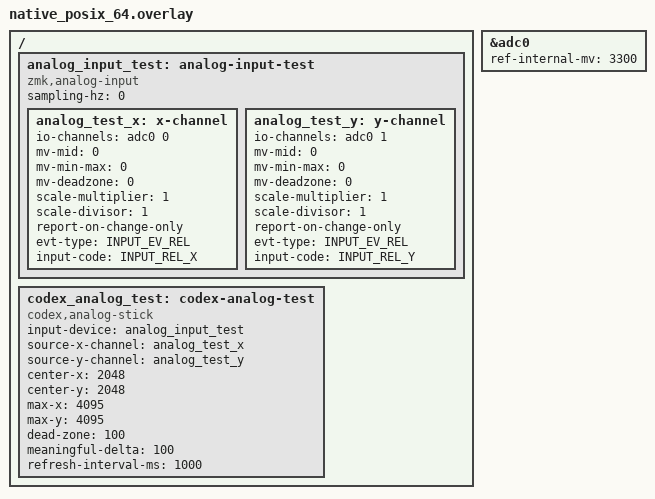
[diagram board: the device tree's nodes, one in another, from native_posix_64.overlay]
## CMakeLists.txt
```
cmake_minimum_required(VERSION 3.20.0)
set(KCONFIG_ROOT ${CMAKE_CURRENT_SOURCE_DIR}/Kconfig)
# The analog tests exercise the pinned badjeff driver, not a mock.  Twister
# passes the module under test through the cached ZEPHYR_EXTRA_MODULES value;
# replace that cache entry before Zephyr discovers modules so the real driver
# contributes its Kconfig, DTS bindings, and source.  The Codex module is
# added below with a distinct binary directory because its relative module
# name ("..") otherwise resolves to the application binary directory.
set(ZEPHYR_EXTRA_MODULES
  "${CMAKE_CURRENT_SOURCE_DIR}/../../../zmk-analog-input-driver"
  CACHE STRING "Modules required by Codex input tests" FORCE
)
# The adapter is added manually below, so declare its DTS root now. The
# fixture also needs ZMK's vendor-prefix registry for zmk,analog-input; DTS
# generation occurs during find_package(Zephyr), before add_subdirectory.
list(APPEND DTS_ROOT
  "${CMAKE_CURRENT_SOURCE_DIR}/../.."
  "${CMAKE_CURRENT_SOURCE_DIR}/../../../zmk/app"
)
# Zephyr discovers the Codex module during find_package(), so publish the
# exact pinned source path before module CMake is evaluated.
set(CODEX_ZMK_ACTIVITY_SOURCE
  "${CMAKE_CURRENT_SOURCE_DIR}/../../../zmk/app/src/activity.c"
  CACHE FILEPATH "Pinned ZMK activity source exercised by this fixture" FORCE
)
find_package(Zephyr REQUIRED HINTS $ENV{ZEPHYR_BASE})
project(codex_input)

execute_process(
  COMMAND west list zmk -f {abspath}
  OUTPUT_VARIABLE ZMK_SOURCE_DIR
  OUTPUT_STRIP_TRAILING_WHITESPACE
  COMMAND_ERROR_IS_FATAL ANY
)

# Compile the exact pinned ZMK activity implementation in this fixture.  The
# Codex module must replace this source through the same audited path used by
# production, not through a test-only activity mock.
target_sources(app PRIVATE "${CODEX_ZMK_ACTIVITY_SOURCE}")

if(NOT TARGET codex_micro)
  add_subdirectory(${CMAKE_CURRENT_SOURCE_DIR}/../..
    ${CMAKE_CURRENT_BINARY_DIR}/codex_micro_module)
endif()

target_include_directories(app PRIVATE
  ${CMAKE_CURRENT_SOURCE_DIR}/../..
  ${CMAKE_CURRENT_SOURCE_DIR}/../../include
  ${ZMK_SOURCE_DIR}/app/include
)
target_include_directories(codex_micro PRIVATE ${ZMK_SOURCE_DIR}/app/include)
target_link_libraries(app PRIVATE codex_micro)
target_sources(app PRIVATE
  src/key_test.c
  src/analog_test.c
  src/activity_test_support.c
  src/touch_state_test.c
)

zephyr_ld_options(
  -Wl,--wrap=codex_zmk_activity_note
  -Wl,--wrap=zmk_keymap_highest_layer_active
  -Wl,--wrap=zmk_keymap_layer_index_to_id
  -Wl,--wrap=zmk_keymap_layer_active
  -Wl,--wrap=zmk_keymap_layer_activate
  -Wl,--wrap=zmk_keymap_layer_deactivate
  -Wl,--wrap=zmk_ble_active_profile_index
  -Wl,--wrap=zmk_ble_prof_select
  -Wl,--wrap=zmk_ble_clear_bonds
  -Wl,--wrap=zmk_endpoints_select_transport
  -Wl,--wrap=zmk_endpoints_selected
)
```

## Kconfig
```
source "Kconfig.zephyr"

# The test application adds the Codex module manually after Zephyr configures;
# include its symbols now so the fixture exercises the production adapter.
rsource "../../Kconfig"

config ZMK_USB
    bool
    default y

config ZMK_HID_REPORT_TYPE_HKRO
    bool
    default y

config ZMK_HID_REPORT_TYPE_NKRO
    bool
    default n

config ZMK_HID_CONSUMER_REPORT_USAGES_FULL
    bool
    default y

config ZMK_HID_CONSUMER_REPORT_USAGES_BASIC
    bool
    default n

config ZMK_HID_INDICATORS
    bool
    default y

config ZMK_POINTING
    bool
    default y

config ZMK_IDLE_TIMEOUT
    int
    default 40

config ZMK_LOG_LEVEL
    int
    default 0

config NRF_STORE_REBOOT_TYPE_GPREGRET
    bool
    default n
```

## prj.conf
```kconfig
CONFIG_ZTEST=y
CONFIG_ZTEST_NEW_API=y
CONFIG_CODEX_MICRO=y
CONFIG_CODEX_ANALOG_STICK=y
CONFIG_INPUT=y
CONFIG_SENSOR=y
CONFIG_ADC=y
CONFIG_ADC_EMUL=y
CONFIG_ANALOG_INPUT=y
CONFIG_ANALOG_INPUT_USE_DTS_ADC_CH_CFG=n
CONFIG_ANALOG_INPUT_ADC_RES=12
CONFIG_ENABLE_HID_INT_OUT_EP=n
```

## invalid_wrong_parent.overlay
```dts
#include <zephyr/dt-bindings/input/input-event-codes.h>

/ {
    wrong_analog_source: wrong-analog-source {
        compatible = "zmk,analog-input";
        sampling-hz = <0>;
        wrong_x: x-channel {
            io-channels = <&adc0 0>;
            mv-mid = <0>; mv-min-max = <0>; mv-deadzone = <0>;
            scale-multiplier = <1>; scale-divisor = <1>;
            report-on-change-only; evt-type = <INPUT_EV_REL>; input-code = <INPUT_REL_X>;
        };
        wrong_y: y-channel {
            io-channels = <&adc0 1>;
            mv-mid = <0>; mv-min-max = <0>; mv-deadzone = <0>;
            scale-multiplier = <1>; scale-divisor = <1>;
            report-on-change-only; evt-type = <INPUT_EV_REL>; input-code = <INPUT_REL_Y>;
        };
    };
    codex_analog_test: codex-analog-test {
        compatible = "codex,analog-stick";
        input-device = <&wrong_analog_source>;
        /* Deliberately wrong: these producer children have another parent. */
        source-x-channel = <&analog_test_x>;
        source-y-channel = <&analog_test_y>;
        center-x = <2048>; center-y = <2048>; max-x = <4095>; max-y = <4095>;
        dead-zone = <100>; meaningful-delta = <100>; refresh-interval-ms = <20>;
    };
};
```

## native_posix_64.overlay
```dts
#include <zephyr/dt-bindings/input/input-event-codes.h>

&adc0 {
    ref-internal-mv = <3300>;
};

/ {
    analog_input_test: analog-input-test {
        compatible = "zmk,analog-input";
        sampling-hz = <0>;

        analog_test_x: x-channel {
            io-channels = <&adc0 0>;
            mv-mid = <0>;
            mv-min-max = <0>;
            mv-deadzone = <0>;
            scale-multiplier = <1>;
            scale-divisor = <1>;
            report-on-change-only;
            evt-type = <INPUT_EV_REL>;
            input-code = <INPUT_REL_X>;
        };

        analog_test_y: y-channel {
            io-channels = <&adc0 1>;
            mv-mid = <0>;
            mv-min-max = <0>;
            mv-deadzone = <0>;
            scale-multiplier = <1>;
            scale-divisor = <1>;
            report-on-change-only;
            evt-type = <INPUT_EV_REL>;
            input-code = <INPUT_REL_Y>;
        };
    };

    codex_analog_test: codex-analog-test {
        compatible = "codex,analog-stick";
        input-device = <&analog_input_test>;
        source-x-channel = <&analog_test_x>;
        source-y-channel = <&analog_test_y>;
        center-x = <2048>;
        center-y = <2048>;
        max-x = <4095>;
        max-y = <4095>;
        dead-zone = <100>;
        meaningful-delta = <100>;
        /* Timer-specific tests use a short override and cancel it; keep the
         * shared callback fixture from leaking a refresh into key tests. */
        refresh-interval-ms = <1000>;
    };
};
```

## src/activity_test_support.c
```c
#include <errno.h>
#include <stddef.h>

#include <zephyr/logging/log.h>

#include <zmk/event_manager.h>
#include <zmk/events/activity_state_changed.h>

#include "activity_test_support.h"

LOG_MODULE_REGISTER(zmk, CONFIG_ZMK_LOG_LEVEL);

const struct zmk_event_type zmk_event_zmk_activity_state_changed = {
    .name = "zmk_activity_state_changed",
};
const struct zmk_event_type zmk_event_zmk_position_state_changed = {
    .name = "zmk_position_state_changed",
};
const struct zmk_event_type zmk_event_zmk_sensor_event = {
    .name = "zmk_sensor_event",
};

static size_t activity_state_event_count;
static size_t activity_note_call_count;
static size_t activity_note_failures_remaining;

extern int __real_codex_zmk_activity_note(void);

int __wrap_codex_zmk_activity_note(void)
{
    activity_note_call_count++;
    if (activity_note_failures_remaining > 0U) {
        activity_note_failures_remaining--;
        return -EIO;
    }
    return __real_codex_zmk_activity_note();
}

int raise_zmk_activity_state_changed(struct zmk_activity_state_changed event)
{
    ARG_UNUSED(event);
    activity_state_event_count++;
    return 0;
}

void codex_activity_test_reset_events(void)
{
    activity_state_event_count = 0U;
    activity_note_call_count = 0U;
    activity_note_failures_remaining = 0U;
}

size_t codex_activity_test_event_count(void)
{
    return activity_state_event_count;
}

void codex_activity_test_fail_next_notes(size_t count)
{
    activity_note_failures_remaining = count;
}

size_t codex_activity_test_note_call_count(void)
{
    return activity_note_call_count;
}
```

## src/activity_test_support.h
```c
#pragma once

#include <stddef.h>

void codex_activity_test_reset_events(void);
size_t codex_activity_test_event_count(void);
void codex_activity_test_fail_next_notes(size_t count);
size_t codex_activity_test_note_call_count(void);
```

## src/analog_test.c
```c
#include <errno.h>
#include <math.h>
#include <string.h>

#include <zephyr/kernel.h>
#include <zephyr/devicetree.h>
#include <zephyr/device.h>
#include <zephyr/dt-bindings/input/input-event-codes.h>
#include <zephyr/drivers/adc/adc_emul.h>
#include <zephyr/drivers/sensor.h>
#include <zephyr/input/input.h>
#include <zephyr/ztest.h>

#include <codex/input.h>
#include <zmk/activity.h>

#include "activity_test_support.h"
#include "input_test_support.h"

extern int set_state(enum zmk_activity_state state);
extern void activity_work_handler(struct k_work *work);

/* These test-only hooks feed the same input callback that production registers. */
static void configure_default(void)
{
    const struct codex_analog_calibration calibration = {
        .center_x = DT_PROP(DT_NODELABEL(codex_analog_test), center_x),
        .center_y = DT_PROP(DT_NODELABEL(codex_analog_test), center_y),
        .max_x = DT_PROP(DT_NODELABEL(codex_analog_test), max_x),
        .max_y = DT_PROP(DT_NODELABEL(codex_analog_test), max_y),
        .dead_zone = DT_PROP(DT_NODELABEL(codex_analog_test), dead_zone),
        .invert_x = false,
        .invert_y = false,
        .meaningful_delta = DT_PROP(DT_NODELABEL(codex_analog_test), meaningful_delta),
        .refresh_interval_ms = 20,
    };

    zassert_ok(codex_analog_test_configure(&calibration));
}

static void reset_analog(void *fixture)
{
    ARG_UNUSED(fixture);
    codex_input_test_reset_capture();
    codex_analog_test_reset();
    configure_default();
    codex_analog_test_set_uptime(0U);
}

static void cleanup_analog(void *fixture)
{
    ARG_UNUSED(fixture);
    codex_analog_test_reset();
}

static bool wait_for_event_count(size_t count, uint32_t timeout_ms)
{
    int64_t deadline = k_uptime_get() + timeout_ms;

    while (codex_input_test_event_count() < count && k_uptime_get() < deadline) {
        k_sleep(K_MSEC(1));
    }
    return codex_input_test_event_count() == count;
}

static bool wait_for_activity_state(enum zmk_activity_state state, uint32_t timeout_ms)
{
    int64_t deadline = k_uptime_get() + timeout_ms;

    while (zmk_activity_get_state() != state && k_uptime_get() < deadline) {
        k_sleep(K_MSEC(1));
    }
    return zmk_activity_get_state() == state;
}

static void enter_idle_and_reset_activity_events(void)
{
    k_sleep(K_MSEC(5));
    zassert_ok(set_state(ZMK_ACTIVITY_IDLE));
    codex_activity_test_reset_events();
}

static void report_codex_sample(int32_t raw_x, int32_t raw_y)
{
    const struct device *codex_source = DEVICE_DT_GET(DT_NODELABEL(analog_input_test));

    zassert_ok(input_report(codex_source, INPUT_EV_REL, INPUT_REL_X, raw_x, false, K_NO_WAIT));
    zassert_ok(input_report(codex_source, INPUT_EV_REL, INPUT_REL_Y, raw_y, true, K_NO_WAIT));
}

ZTEST(analog, test_complete_codex_sample_inside_dead_zone_does_not_wake_idle)
{
    enter_idle_and_reset_activity_events();
    report_codex_sample(2049, 2048);
    k_sleep(K_MSEC(5));
    zassert_equal(zmk_activity_get_state(), ZMK_ACTIVITY_IDLE);
    zassert_equal(codex_activity_test_event_count(), 0U);
}

ZTEST(analog, test_codex_sample_strictly_above_distance_point_one_wakes_once)
{
    enter_idle_and_reset_activity_events();
    report_codex_sample(4095, 2048);
    zassert_true(wait_for_activity_state(ZMK_ACTIVITY_ACTIVE, 20U));
    zassert_equal(codex_activity_test_event_count(), 1U);
}

ZTEST(analog, test_unrelated_pointing_device_retains_standard_zmk_activity)
{
    const struct device *ordinary_pointing = DEVICE_DT_GET(DT_NODELABEL(adc0));

    enter_idle_and_reset_activity_events();
    zassert_ok(input_report(ordinary_pointing, INPUT_EV_REL, INPUT_REL_X, 1, true, K_NO_WAIT));
    zassert_true(wait_for_activity_state(ZMK_ACTIVITY_ACTIVE, 20U));
    zassert_equal(codex_activity_test_event_count(), 1U);
}

ZTEST(analog, test_codex_noise_does_not_renew_standard_zmk_idle_timer)
{
    const struct device *ordinary_pointing = DEVICE_DT_GET(DT_NODELABEL(adc0));

    enter_idle_and_reset_activity_events();
    zassert_ok(input_report(ordinary_pointing, INPUT_EV_REL, INPUT_REL_X, 1, true, K_NO_WAIT));
    zassert_true(wait_for_activity_state(ZMK_ACTIVITY_ACTIVE, 20U));
    k_sleep(K_MSEC(CONFIG_ZMK_IDLE_TIMEOUT + 5));
    report_codex_sample(2049, 2048);
    k_sleep(K_MSEC(5));
    activity_work_handler(NULL);
    zassert_equal(zmk_activity_get_state(), ZMK_ACTIVITY_IDLE);
}

ZTEST(analog, test_center_is_exact_zero)
{
    struct codex_radial value = codex_analog_normalize(2048, 2048);

    zassert_equal(value.distance, 0.0f);
    zassert_equal(value.angle, 0.0f);
}

ZTEST(analog, test_cardinal_and_wrapped_quadrant_angles_are_normalized)
{
    struct codex_radial right = codex_analog_normalize(4095, 2048);
    struct codex_radial up = codex_analog_normalize(2048, 4095);
    struct codex_radial left = codex_analog_normalize(0, 2048);
    struct codex_radial down = codex_analog_normalize(2048, 0);
    struct codex_radial lower_right = codex_analog_normalize(4095, 0);

    zassert_within(right.angle, 0.0f, 0.01f);
    zassert_within(up.angle, 0.25f, 0.01f);
    zassert_within(left.angle, 0.5f, 0.01f);
    zassert_within(down.angle, 0.75f, 0.01f);
    zassert_true(lower_right.angle > 0.75f && lower_right.angle < 1.0f);
}

ZTEST(analog, test_dead_zone_edge_and_circular_clamp)
{
    struct codex_radial inside = codex_analog_normalize(2148, 2048);
    struct codex_radial outside = codex_analog_normalize(2149, 2048);
    struct codex_radial diagonal = codex_analog_normalize(4095, 4095);

    zassert_equal(inside.distance, 0.0f);
    zassert_true(outside.distance > 0.0f);
    zassert_within(diagonal.distance, 1.0f, 0.001f);
}

ZTEST(analog, test_non_symmetric_axis_calibration_and_inversion)
{
    const struct codex_analog_calibration calibration = {
        .center_x = 1000,
        .center_y = 3000,
        .max_x = 3000,
        .max_y = 3500,
        .dead_zone = 0,
        .invert_x = true,
        .invert_y = false,
        .meaningful_delta = 100,
        .refresh_interval_ms = 20,
    };
    struct codex_radial value;

    zassert_ok(codex_analog_test_configure(&calibration));
    value = codex_analog_normalize(3000, 3000);
    zassert_within(value.angle, 0.5f, 0.01f);
    zassert_within(value.distance, 1.0f, 0.001f);
}

ZTEST(analog, test_input_pair_waits_for_sync_and_uses_last_other_axis)
{
    zassert_ok(codex_analog_test_input_event(INPUT_REL_X, 4095, false));
    k_sleep(K_MSEC(2));
    zassert_equal(codex_input_test_event_count(), 0U);
    zassert_ok(codex_analog_test_input_event(INPUT_REL_Y, 2048, true));
    codex_input_test_wait_for_events(1U);
    zassert_equal(strcmp(codex_input_test_event(0U),
                         "{\"m\":\"v.oai.rad\",\"p\":{\"a\":0,\"d\":1}}"), 0);

    zassert_ok(codex_analog_test_input_event(INPUT_REL_X, 2048, true));
    codex_input_test_wait_for_events(2U);
    zassert_equal(strcmp(codex_input_test_event(1U),
                         "{\"m\":\"v.oai.rad\",\"p\":{\"a\":0,\"d\":0}}"), 0);
}

ZTEST(analog, test_registered_callback_uses_center_for_first_pure_axis_and_filters_events)
{
    const struct device *source = DEVICE_DT_GET(DT_NODELABEL(analog_input_test));

    zassert_ok(input_report(NULL, INPUT_EV_REL, INPUT_REL_X, 4095, true, K_NO_WAIT));
    k_sleep(K_MSEC(2));
    zassert_equal(codex_input_test_event_count(), 0U);
    zassert_ok(input_report(source, INPUT_EV_KEY, INPUT_REL_X, 4095, true, K_NO_WAIT));
    zassert_ok(input_report(source, INPUT_EV_REL, INPUT_REL_WHEEL, 4095, true, K_NO_WAIT));
    k_sleep(K_MSEC(2));
    zassert_equal(codex_input_test_event_count(), 0U);

    zassert_ok(input_report(source, INPUT_EV_REL, INPUT_REL_X, 4095, true, K_NO_WAIT));
    codex_input_test_wait_for_events(1U);
    zassert_equal(strcmp(codex_input_test_event(0U),
                         "{\"m\":\"v.oai.rad\",\"p\":{\"a\":0,\"d\":1}}"), 0);
}

ZTEST(analog, test_registered_callback_first_pure_y_and_sync_boundary_use_cached_center)
{
    const struct device *source = DEVICE_DT_GET(DT_NODELABEL(analog_input_test));

    zassert_ok(input_report(source, INPUT_EV_REL, INPUT_REL_Y, 4095, false, K_NO_WAIT));
    k_sleep(K_MSEC(2));
    zassert_equal(codex_input_test_event_count(), 0U);
    zassert_ok(input_report(source, INPUT_EV_REL, INPUT_REL_Y, 4095, true, K_NO_WAIT));
    codex_input_test_wait_for_events(1U);
    zassert_equal(strcmp(codex_input_test_event(0U),
                         "{\"m\":\"v.oai.rad\",\"p\":{\"a\":0.25,\"d\":1}}"), 0);
}

ZTEST(analog, test_patched_upstream_driver_reports_changed_frame_then_returns_on_unchanged_frame)
{
    const struct device *adc = DEVICE_DT_GET(DT_NODELABEL(adc0));
    const struct device *source = DEVICE_DT_GET(DT_NODELABEL(analog_input_test));

    zassert_true(device_is_ready(adc));
    zassert_true(device_is_ready(source));
    /* The pinned driver initializes its ADC sequence asynchronously. */
    k_sleep(K_MSEC(30));
    zassert_ok(adc_emul_const_value_set(adc, 0U, 4095U));
    zassert_ok(adc_emul_const_value_set(adc, 1U, 2048U));
    zassert_ok(sensor_sample_fetch(source));
    codex_input_test_wait_for_events(1U);

    /* This invokes the patched reverse scan with every channel unchanged. */
    zassert_ok(sensor_sample_fetch(source));
    k_sleep(K_MSEC(2));
    zassert_equal(codex_input_test_event_count(), 1U);
}

ZTEST(analog, test_held_position_refreshes_without_new_input_and_center_is_not_suppressed)
{
    zassert_ok(codex_analog_test_input_event(INPUT_REL_X, 4095, false));
    zassert_ok(codex_analog_test_input_event(INPUT_REL_Y, 2048, true));
    codex_input_test_wait_for_events(1U);

    /* No subsequent input arrives: the delayable work must refresh the hold. */
    codex_input_test_wait_for_events(2U);
    zassert_ok(codex_analog_test_input_event(INPUT_REL_X, 4080, true));

    codex_analog_test_set_uptime(20U);
    zassert_ok(codex_analog_test_input_event(INPUT_REL_X, 4080, true));
    codex_input_test_wait_for_events(3U);
    zassert_ok(codex_analog_test_input_event(INPUT_REL_X, 2048, true));
    codex_input_test_wait_for_events(4U);
    zassert_equal(strcmp(codex_input_test_event(3U),
                         "{\"m\":\"v.oai.rad\",\"p\":{\"a\":0,\"d\":0}}"), 0);
}

ZTEST(analog, test_suppressed_sample_inherits_armed_refresh_without_moving_deadline)
{
    const struct codex_analog_calibration calibration = {
        .center_x = 2048,
        .center_y = 2048,
        .max_x = 4095,
        .max_y = 4095,
        .dead_zone = 100,
        .meaningful_delta = 200,
        .refresh_interval_ms = 100,
    };

    zassert_ok(codex_analog_test_configure(&calibration));
    zassert_ok(codex_input_radial_emit((struct codex_radial){.angle = 0.2f, .distance = 0.5f}));
    codex_input_test_wait_for_events(1U);

    k_sleep(K_MSEC(60));
    zassert_ok(codex_input_radial_emit((struct codex_radial){.angle = 0.2f, .distance = 0.505f}));
    zassert_true(wait_for_event_count(2U, 70U));
    zassert_equal(strcmp(codex_input_test_event(1U),
                         "{\"m\":\"v.oai.rad\",\"p\":{\"a\":0.2,\"d\":0.505}}"), 0);

    zassert_ok(codex_input_radial_emit((struct codex_radial){.angle = 0.0f, .distance = 0.0f}));
    codex_input_test_wait_for_events(3U);
    k_sleep(K_MSEC(120));
    zassert_equal(codex_input_test_event_count(), 3U);
}

ZTEST(analog, test_suppressed_sample_after_inflight_emit_arms_latest_refresh)
{
    const struct codex_analog_calibration calibration = {
        .center_x = 2048,
        .center_y = 2048,
        .max_x = 4095,
        .max_y = 4095,
        .dead_zone = 100,
        .meaningful_delta = 200,
        .refresh_interval_ms = 40,
    };

    zassert_ok(codex_analog_test_configure(&calibration));
    codex_input_test_set_block_router(true);
    zassert_ok(codex_input_radial_emit((struct codex_radial){.angle = 0.2f, .distance = 0.5f}));
    zassert_ok(codex_input_test_wait_router_entered());
    zassert_ok(codex_input_radial_emit((struct codex_radial){.angle = 0.2f, .distance = 0.505f}));
    codex_input_test_release_router();
    codex_input_test_set_block_router(false);

    zassert_true(wait_for_event_count(2U, 80U));
    zassert_equal(strcmp(codex_input_test_event(1U),
                         "{\"m\":\"v.oai.rad\",\"p\":{\"a\":0.2,\"d\":0.505}}"), 0);
    zassert_ok(codex_input_radial_emit((struct codex_radial){.angle = 0.0f, .distance = 0.0f}));
    codex_input_test_wait_for_events(3U);
    k_sleep(K_MSEC(60));
    zassert_equal(codex_input_test_event_count(), 3U);
}

ZTEST(analog, test_center_is_emitted_once_and_can_be_emitted_again)
{
    zassert_ok(codex_input_radial_emit((struct codex_radial){.angle = 0.0f, .distance = 0.0f}));
    codex_input_test_wait_for_events(1U);
    zassert_ok(codex_input_radial_emit((struct codex_radial){.angle = 0.0f, .distance = 0.0f}));
    k_sleep(K_MSEC(2));
    zassert_equal(codex_input_test_event_count(), 1U);
    zassert_ok(codex_input_radial_emit((struct codex_radial){.angle = 0.25f, .distance = 0.8f}));
    codex_input_test_wait_for_events(2U);
    zassert_ok(codex_input_radial_emit((struct codex_radial){.angle = 0.0f, .distance = 0.0f}));
    codex_input_test_wait_for_events(3U);
}

ZTEST(analog, test_invalid_radial_values_are_rejected)
{
    zassert_equal(codex_input_radial_emit((struct codex_radial){.angle = NAN, .distance = 0.5f}),
                  -EINVAL);
    zassert_equal(codex_input_radial_emit((struct codex_radial){.angle = 0.0f, .distance = NAN}),
                  -EINVAL);
    zassert_equal(codex_input_radial_emit((struct codex_radial){.angle = 0.0f, .distance = 1.1f}),
                  -EINVAL);
}

ZTEST(analog, test_latest_mailbox_handles_pressure_and_router_error)
{
    const struct codex_analog_calibration calibration = {
        .center_x = 2048,
        .center_y = 2048,
        .max_x = 4095,
        .max_y = 4095,
        .dead_zone = 100,
        .meaningful_delta = 0,
        .refresh_interval_ms = 20,
    };

    zassert_ok(codex_analog_test_configure(&calibration));
    codex_input_test_set_block_router(true);
    zassert_ok(codex_input_radial_emit((struct codex_radial){.angle = 0.1f, .distance = 0.5f}));
    zassert_ok(codex_input_test_wait_router_entered());
    for (size_t i = 0U; i < CONFIG_CODEX_ANALOG_QUEUE_DEPTH; i++) {
        zassert_ok(codex_input_radial_emit((struct codex_radial){.angle = 0.1f + (float)i / 100.0f,
                                                                    .distance = 0.5f}));
    }
    zassert_ok(codex_input_radial_emit((struct codex_radial){.angle = 0.9f, .distance = 0.5f}));
    codex_input_test_release_router();
    codex_input_test_set_block_router(false);
    codex_input_test_wait_for_events(2U);
    zassert_true(strstr(codex_input_test_event(1U), "\"a\":0.9") != NULL);

    codex_input_test_set_router_result(-ENOMSG);
    zassert_ok(codex_input_radial_emit((struct codex_radial){.angle = 0.3f, .distance = 0.5f}));
    codex_input_test_wait_for_events(3U);
    codex_input_test_set_router_result(0);
    zassert_ok(codex_input_radial_emit((struct codex_radial){.angle = 0.4f, .distance = 0.5f}));
    codex_input_test_wait_for_events(4U);
}

ZTEST(analog, test_later_public_center_overwrites_older_raw_pending_sample)
{
    codex_input_test_set_block_router(true);
    zassert_ok(codex_input_radial_emit((struct codex_radial){.angle = 0.1f, .distance = 0.8f}));
    zassert_ok(codex_input_test_wait_router_entered());
    zassert_ok(codex_analog_test_input_event(INPUT_REL_X, 4095, true));
    zassert_ok(codex_input_radial_emit((struct codex_radial){.angle = 0.0f, .distance = 0.0f}));
    codex_input_test_release_router();
    codex_input_test_set_block_router(false);
    codex_input_test_wait_for_events(2U);
    zassert_equal(strcmp(codex_input_test_event(1U),
                         "{\"m\":\"v.oai.rad\",\"p\":{\"a\":0,\"d\":0}}"), 0);
    k_sleep(K_MSEC(40));
    zassert_equal(codex_input_test_event_count(), 2U);
}

ZTEST(analog, test_blocked_worker_out_and_back_keeps_meaningful_activity_latched)
{
    enter_idle_and_reset_activity_events();

    /* Public radial input blocks the sole worker but is not physical activity. */
    codex_input_test_set_block_router(true);
    zassert_ok(codex_input_radial_emit((struct codex_radial){.angle = 0.1f, .distance = 0.8f}));
    zassert_ok(codex_input_test_wait_router_entered());

    /* A qualifying complete raw sample is immediately overwritten by center
     * in the latest-wins RPC mailbox before the worker can consume either. */
    zassert_ok(codex_analog_test_input_event(INPUT_REL_X, 4095, true));
    zassert_ok(codex_analog_test_input_event(INPUT_REL_X, 2048, true));

    codex_input_test_release_router();
    codex_input_test_set_block_router(false);
    codex_input_test_wait_for_events(2U);
    zassert_equal(strcmp(codex_input_test_event(1U),
                         "{\"m\":\"v.oai.rad\",\"p\":{\"a\":0,\"d\":0}}"), 0);
    zassert_true(wait_for_activity_state(ZMK_ACTIVITY_ACTIVE, 20U));
    zassert_equal(codex_activity_test_event_count(), 1U);
}

ZTEST(analog, test_failed_activity_note_is_requeued_without_sticking_latch)
{
    uint32_t invocation_count;

    enter_idle_and_reset_activity_events();
    codex_activity_test_fail_next_notes(1U);
    invocation_count = codex_analog_test_work_invocation_count();

    zassert_ok(codex_analog_test_input_event(INPUT_REL_X, 4095, true));
    zassert_true(wait_for_activity_state(ZMK_ACTIVITY_ACTIVE, 20U));
    zassert_equal(codex_activity_test_note_call_count(), 2U);
    zassert_true(codex_analog_test_work_invocation_count() >= invocation_count + 2U,
                 "failed activity note was not retried in a later work invocation");
    zassert_equal(codex_activity_test_event_count(), 1U);

    /* A later sub-threshold sample cannot reveal a stale pending latch. */
    zassert_ok(set_state(ZMK_ACTIVITY_IDLE));
    codex_activity_test_reset_events();
    zassert_ok(codex_analog_test_input_event(INPUT_REL_X, 2049, true));
    k_sleep(K_MSEC(5));
    zassert_equal(zmk_activity_get_state(), ZMK_ACTIVITY_IDLE);
    zassert_equal(codex_activity_test_note_call_count(), 0U);
}

ZTEST(analog, test_later_public_noncenter_overwrites_older_raw_and_refreshes)
{
    codex_input_test_set_block_router(true);
    zassert_ok(codex_input_radial_emit((struct codex_radial){.angle = 0.1f, .distance = 0.8f}));
    zassert_ok(codex_input_test_wait_router_entered());
    zassert_ok(codex_analog_test_input_event(INPUT_REL_X, 4095, true));
    zassert_ok(codex_input_radial_emit((struct codex_radial){.angle = 0.25f, .distance = 0.6f}));
    codex_input_test_release_router();
    codex_input_test_set_block_router(false);
    codex_input_test_wait_for_events(2U);
    zassert_true(strstr(codex_input_test_event(1U), "\"a\":0.25,\"d\":0.6") != NULL);
    codex_input_test_wait_for_events(3U);
    zassert_true(strstr(codex_input_test_event(2U), "\"a\":0.25,\"d\":0.6") != NULL);
}

ZTEST(analog, test_later_raw_overwrites_older_public_pending_sample)
{
    codex_input_test_set_block_router(true);
    zassert_ok(codex_input_radial_emit((struct codex_radial){.angle = 0.1f, .distance = 0.8f}));
    zassert_ok(codex_input_test_wait_router_entered());
    zassert_ok(codex_input_radial_emit((struct codex_radial){.angle = 0.25f, .distance = 0.6f}));
    zassert_ok(codex_analog_test_input_event(INPUT_REL_X, 4095, true));
    codex_input_test_release_router();
    codex_input_test_set_block_router(false);
    codex_input_test_wait_for_events(2U);
    zassert_true(strstr(codex_input_test_event(1U), "\"a\":0,\"d\":1") != NULL);
    codex_input_test_wait_for_events(3U);
    zassert_true(strstr(codex_input_test_event(2U), "\"a\":0,\"d\":1") != NULL);
}

ZTEST(analog, test_blocked_worker_coalesces_final_center_and_cancels_stale_refresh)
{
    zassert_ok(codex_analog_test_input_event(INPUT_REL_X, 4095, false));
    zassert_ok(codex_analog_test_input_event(INPUT_REL_Y, 2048, true));
    codex_input_test_wait_for_events(1U);

    codex_input_test_set_block_router(true);
    zassert_ok(codex_input_radial_emit((struct codex_radial){.angle = 0.1f, .distance = 0.8f}));
    zassert_ok(codex_input_test_wait_router_entered());
    for (size_t i = 0U; i < CONFIG_CODEX_ANALOG_QUEUE_DEPTH + 2U; i++) {
        zassert_ok(codex_analog_test_input_event(INPUT_REL_X, 4095 - (int32_t)i, true));
    }
    zassert_ok(codex_analog_test_input_event(INPUT_REL_X, 2048, true));
    codex_input_test_release_router();
    codex_input_test_set_block_router(false);
    codex_input_test_wait_for_events(3U);
    zassert_equal(strcmp(codex_input_test_event(2U),
                         "{\"m\":\"v.oai.rad\",\"p\":{\"a\":0,\"d\":0}}"), 0);
    k_sleep(K_MSEC(40));
    zassert_equal(codex_input_test_event_count(), 3U);
}

ZTEST(analog, test_blocked_worker_coalesces_final_noncenter_and_router_error_continues)
{
    codex_input_test_set_block_router(true);
    zassert_ok(codex_input_radial_emit((struct codex_radial){.angle = 0.1f, .distance = 0.4f}));
    zassert_ok(codex_input_test_wait_router_entered());
    for (size_t i = 0U; i < CONFIG_CODEX_ANALOG_QUEUE_DEPTH + 2U; i++) {
        zassert_ok(codex_analog_test_input_event(INPUT_REL_X, 2048 + (int32_t)i, true));
    }
    zassert_ok(codex_analog_test_input_event(INPUT_REL_X, 4095, true));
    codex_input_test_release_router();
    codex_input_test_set_block_router(false);
    codex_input_test_wait_for_events(2U);
    zassert_true(strstr(codex_input_test_event(1U), "\"d\":1") != NULL);

    codex_input_test_set_router_result(-ENOMSG);
    zassert_ok(codex_input_radial_emit((struct codex_radial){.angle = 0.3f, .distance = 0.6f}));
    codex_input_test_wait_for_events(3U);
    codex_input_test_set_router_result(0);
    zassert_ok(codex_input_radial_emit((struct codex_radial){.angle = 0.4f, .distance = 0.6f}));
    codex_input_test_wait_for_events(4U);
}

ZTEST(analog, test_refresh_comparison_is_wrap_safe)
{
    codex_analog_test_set_uptime(UINT32_MAX - 5U);
    zassert_ok(codex_input_radial_emit((struct codex_radial){.angle = 0.2f, .distance = 0.5f}));
    codex_input_test_wait_for_events(1U);
    codex_analog_test_set_uptime(15U);
    zassert_ok(codex_input_radial_emit((struct codex_radial){.angle = 0.2f, .distance = 0.5f}));
    codex_input_test_wait_for_events(2U);
}

ZTEST_SUITE(analog, NULL, NULL, reset_analog, cleanup_analog, NULL);
```

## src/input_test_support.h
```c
#pragma once

#include <stdbool.h>
#include <stddef.h>

void codex_input_test_reset_capture(void);
void codex_input_test_wait_for_events(size_t count);
const char *codex_input_test_event(size_t index);
size_t codex_input_test_event_count(void);
void codex_input_test_set_router_result(int result);
void codex_input_test_set_block_router(bool block);
int codex_input_test_wait_router_entered(void);
void codex_input_test_release_router(void);
```

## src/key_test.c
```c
#include <errno.h>
#include <stdbool.h>
#include <stddef.h>
#include <stdint.h>
#include <string.h>

#include <zephyr/kernel.h>
#include <zephyr/ztest.h>

#include <codex/framing.h>
#include <codex/input.h>

#include "input_test_support.h"

#define CAPTURE_MAX 48U

static char sent[CAPTURE_MAX][80];
static size_t sent_count;
static int router_result;
static int router_scripted_results[CAPTURE_MAX];
static size_t router_scripted_count;
static bool block_router;
K_SEM_DEFINE(router_entered, 0, 1);
K_SEM_DEFINE(router_release, 0, 1);
K_SEM_DEFINE(blocker_entered, 0, 1);
K_SEM_DEFINE(blocker_release, 0, 1);

static void system_work_blocker(struct k_work *work)
{
    ARG_UNUSED(work);
    k_sem_give(&blocker_entered);
    (void)k_sem_take(&blocker_release, K_FOREVER);
}

K_WORK_DEFINE(blocker_work, system_work_blocker);

int codex_router_send_json(enum codex_channel channel, const uint8_t *json,
                           size_t len)
{
    zassert_equal(channel, CODEX_CHANNEL_RPC);
    zassert_true(sent_count < CAPTURE_MAX);
    zassert_true(len < sizeof(sent[0]));
    memcpy(sent[sent_count], json, len);
    sent[sent_count][len] = '\0';
    sent_count++;
    if (block_router) {
        k_sem_give(&router_entered);
        (void)k_sem_take(&router_release, K_FOREVER);
    }
    if (sent_count <= router_scripted_count) {
        return router_scripted_results[sent_count - 1U];
    }
    return router_result;
}

static void reset_case(void *fixture)
{
    ARG_UNUSED(fixture);
    codex_input_test_reset_capture();
}

void codex_input_test_reset_capture(void)
{
    memset(sent, 0, sizeof(sent));
    sent_count = 0U;
    router_result = 0;
    memset(router_scripted_results, 0, sizeof(router_scripted_results));
    router_scripted_count = 0U;
    block_router = false;
    k_sem_reset(&router_entered);
    k_sem_reset(&router_release);
    k_sem_reset(&blocker_entered);
    k_sem_reset(&blocker_release);
    codex_input_test_reset();
}

void codex_input_test_wait_for_events(size_t count)
{
    int64_t deadline = k_uptime_get() + 200;

    while (sent_count < count && k_uptime_get() < deadline) {
        k_sleep(K_MSEC(1));
    }
    zassert_equal(sent_count, count);
}

const char *codex_input_test_event(size_t index)
{
    zassert_true(index < sent_count);
    return sent[index];
}

size_t codex_input_test_event_count(void)
{
    return sent_count;
}

void codex_input_test_set_router_result(int result)
{
    router_result = result;
}

void codex_input_test_set_block_router(bool block)
{
    block_router = block;
}

int codex_input_test_wait_router_entered(void)
{
    return k_sem_take(&router_entered, K_MSEC(100));
}

void codex_input_test_release_router(void)
{
    k_sem_give(&router_release);
}

#define wait_for_events codex_input_test_wait_for_events

static void assert_event(size_t index, const char *key, unsigned int action,
                         unsigned int agent)
{
    char expected[80];

    snprintk(expected, sizeof(expected),
             "{\"m\":\"v.oai.hid\",\"p\":{\"k\":\"%s\",\"act\":%u,\"ag\":%u}}",
             key, action, agent);
    zassert_equal(strcmp(sent[index], expected), 0, "%s", sent[index]);
}

ZTEST(input, test_all_agent_keys_use_their_matching_agent_index)
{
    static const char *const ids[] = {"AG00", "AG01", "AG02", "AG03", "AG04", "AG05"};

    for (uint8_t agent = 0U; agent < ARRAY_SIZE(ids); agent++) {
        zassert_ok(codex_input_key(ids[agent], true, agent));
        zassert_ok(codex_input_key(ids[agent], false, agent));
    }
    wait_for_events(ARRAY_SIZE(ids) * 2U);
    for (uint8_t agent = 0U; agent < ARRAY_SIZE(ids); agent++) {
        assert_event(agent * 2U, ids[agent], 1U, agent);
        assert_event(agent * 2U + 1U, ids[agent], 0U, agent);
    }
}

ZTEST(input, test_repeated_edges_are_forwarded_without_local_deduplication)
{
    zassert_ok(codex_input_key("ACT10", true, 0U));
    zassert_ok(codex_input_key("ACT10", true, 0U));
    zassert_ok(codex_input_key("ACT10", false, 0U));
    zassert_ok(codex_input_key("ACT10", false, 0U));
    wait_for_events(4U);

    assert_event(0U, "ACT10", 1U, 0U);
    assert_event(1U, "ACT10", 1U, 0U);
    assert_event(2U, "ACT10", 0U, 0U);
    assert_event(3U, "ACT10", 0U, 0U);
}

ZTEST(input, test_all_action_keys_emit_each_uncoalesced_edge)
{
    static const char *const ids[] = {"ACT06", "ACT07", "ACT08", "ACT09", "ACT10", "ACT11", "ACT12"};

    for (size_t index = 0U; index < ARRAY_SIZE(ids); index++) {
        zassert_ok(codex_input_key(ids[index], true, 0U));
        zassert_ok(codex_input_key(ids[index], false, 0U));
    }
    wait_for_events(ARRAY_SIZE(ids) * 2U);
    for (size_t index = 0U; index < ARRAY_SIZE(ids); index++) {
        assert_event(index * 2U, ids[index], 1U, 0U);
        assert_event(index * 2U + 1U, ids[index], 0U, 0U);
    }
}

ZTEST(input, test_act10_and_act11_solo_overlap_and_interleaved_edges_remain_independent)
{
    zassert_ok(codex_input_key("ACT10", true, 0U));
    zassert_ok(codex_input_key("ACT11", true, 0U));
    zassert_ok(codex_input_key("ACT10", false, 0U));
    zassert_ok(codex_input_key("ACT11", false, 0U));
    zassert_ok(codex_input_key("ACT11", true, 0U));
    zassert_ok(codex_input_key("ACT11", false, 0U));
    zassert_ok(codex_input_key("ACT10", true, 0U));
    zassert_ok(codex_input_key("ACT11", true, 0U));
    zassert_ok(codex_input_key("ACT11", false, 0U));
    zassert_ok(codex_input_key("ACT10", false, 0U));
    wait_for_events(10U);

    assert_event(0U, "ACT10", 1U, 0U);
    assert_event(1U, "ACT11", 1U, 0U);
    assert_event(2U, "ACT10", 0U, 0U);
    assert_event(3U, "ACT11", 0U, 0U);
    assert_event(4U, "ACT11", 1U, 0U);
    assert_event(5U, "ACT11", 0U, 0U);
    assert_event(6U, "ACT10", 1U, 0U);
    assert_event(7U, "ACT11", 1U, 0U);
    assert_event(8U, "ACT11", 0U, 0U);
    assert_event(9U, "ACT10", 0U, 0U);
}

ZTEST(input, test_encoder_push_and_detents_use_exact_hardware_compatible_events)
{
    zassert_ok(codex_input_encoder_press(true));
    zassert_ok(codex_input_encoder_press(false));
    zassert_ok(codex_input_encoder_tick(1));
    zassert_ok(codex_input_encoder_tick(-1));
    wait_for_events(4U);

    assert_event(0U, "ENC_CLK", 1U, 0U);
    assert_event(1U, "ENC_CLK", 0U, 0U);
    /* Hardware-compatible detents are one momentary act:1 notification. */
    assert_event(2U, "ENC_CW", 1U, 0U);
    assert_event(3U, "ENC_CC", 1U, 0U);
}

ZTEST(input, test_rejects_unknown_or_mismatched_ids_without_emitting_json)
{
    zassert_equal(codex_input_key(NULL, true, 0U), -EINVAL);
    zassert_equal(codex_input_key("ACT10\",\"owned\":1", true, 0U), -EINVAL);
    zassert_equal(codex_input_key("AG03", true, 2U), -EINVAL);
    zassert_equal(codex_input_key("ACT10", true, 1U), -EINVAL);
    zassert_equal(codex_input_encoder_tick(0), -EINVAL);
    zassert_equal(codex_input_encoder_tick(2), -EINVAL);
    k_sleep(K_MSEC(5));
    zassert_equal(sent_count, 0U);
}

ZTEST(input, test_full_queue_returns_enospc_while_worker_is_blocked)
{
    block_router = true;
    zassert_ok(codex_input_key("ACT06", true, 0U));
    zassert_ok(k_sem_take(&router_entered, K_MSEC(100)));
    for (size_t index = 0U; index < CONFIG_CODEX_INPUT_EVENT_QUEUE_DEPTH; index++) {
        zassert_ok(codex_input_key("ACT07", true, 0U));
    }
    zassert_equal(codex_input_key("ACT08", true, 0U), -ENOSPC);
    k_sem_give(&router_release);
    block_router = false;
    wait_for_events(CONFIG_CODEX_INPUT_EVENT_QUEUE_DEPTH + 1U);
}

ZTEST(input, test_router_error_does_not_stop_the_production_worker)
{
    router_result = -ENOTCONN;
    zassert_ok(codex_input_key("ACT10", true, 0U));
    wait_for_events(1U);
    router_result = 0;
    zassert_ok(codex_input_key("ACT11", true, 0U));
    wait_for_events(2U);
    assert_event(0U, "ACT10", 1U, 0U);
    assert_event(1U, "ACT11", 1U, 0U);
}

ZTEST(input, test_router_enomsg_consumes_only_its_event_and_drains_fifo)
{
    zassert_true(k_work_submit(&blocker_work) >= 0);
    zassert_ok(k_sem_take(&blocker_entered, K_MSEC(100)));
    router_scripted_results[0] = -ENOMSG;
    router_scripted_count = 1U;
    zassert_ok(codex_input_key("ACT10", true, 0U));
    zassert_ok(codex_input_key("ACT11", true, 0U));
    k_sem_give(&blocker_release);
    wait_for_events(2U);
    assert_event(0U, "ACT10", 1U, 0U);
    assert_event(1U, "ACT11", 1U, 0U);
}

ZTEST_SUITE(input, NULL, NULL, reset_case, NULL, NULL);
```
